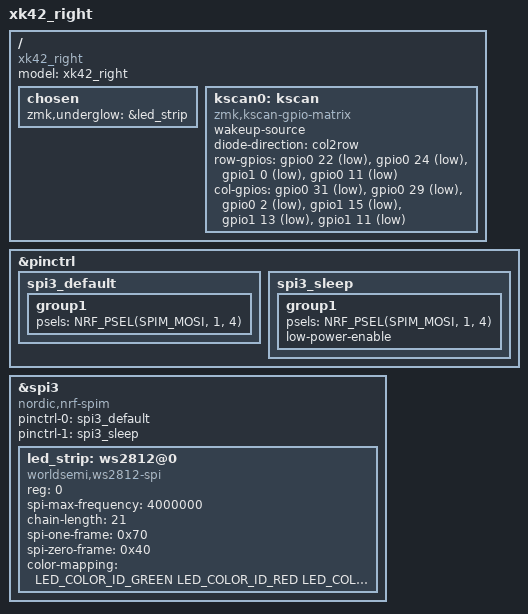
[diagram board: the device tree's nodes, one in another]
/*
* Copyright (c) 2020 The ZMK Contributors
*
* SPDX-License-Identifier: MIT
*/

#include "xk42.dtsi"
#include <dt-bindings/led/led.h>

/ {
    model = "xk42_right";
    compatible = "xk42_right";

    chosen {
        zmk,underglow = &led_strip;
    };

    kscan0: kscan {
        compatible = "zmk,kscan-gpio-matrix";
        wakeup-source;

        diode-direction = "col2row";
        row-gpios
            = <&gpio0 22 (GPIO_ACTIVE_LOW | GPIO_PULL_DOWN)>
            , <&gpio0 24 (GPIO_ACTIVE_LOW | GPIO_PULL_DOWN)>
            , <&gpio1  0 (GPIO_ACTIVE_LOW | GPIO_PULL_DOWN)>
            , <&gpio0 11 (GPIO_ACTIVE_LOW | GPIO_PULL_DOWN)>
            ;
        col-gpios
            = <&gpio0 31 (GPIO_ACTIVE_LOW | GPIO_PULL_UP)>
            , <&gpio0 29 (GPIO_ACTIVE_LOW | GPIO_PULL_UP)>
            , <&gpio0  2 (GPIO_ACTIVE_LOW | GPIO_PULL_UP)>
            , <&gpio1 15 (GPIO_ACTIVE_LOW | GPIO_PULL_UP)>
            , <&gpio1 13 (GPIO_ACTIVE_LOW | GPIO_PULL_UP)>
            , <&gpio1 11 (GPIO_ACTIVE_LOW | GPIO_PULL_UP)>
            ;
    };
};

&pinctrl {
    spi3_default: spi3_default {
        group1 {
            psels = <NRF_PSEL(SPIM_MOSI, 1, 4)>;
        };
    };

    spi3_sleep: spi3_sleep {
        group1 {
            psels = <NRF_PSEL(SPIM_MOSI, 1, 4)>;
            low-power-enable;
        };
    };
};

&spi3 {
    compatible = "nordic,nrf-spim";
    status = "okay";

    pinctrl-0 = <&spi3_default>;
    pinctrl-1 = <&spi3_sleep>;
    pinctrl-names = "default", "sleep";

    led_strip: ws2812@0 {
        compatible = "worldsemi,ws2812-spi";

        /* SPI */
        reg = <0>; /* ignored, but necessary for SPI bindings */
        spi-max-frequency = <4000000>;

        /* WS2812 */
        chain-length = <21>; /* number of LEDs */
        spi-one-frame = <0x70>;
        spi-zero-frame = <0x40>;
        color-mapping = <LED_COLOR_ID_GREEN
            LED_COLOR_ID_RED
            LED_COLOR_ID_BLUE>;
    };
};
